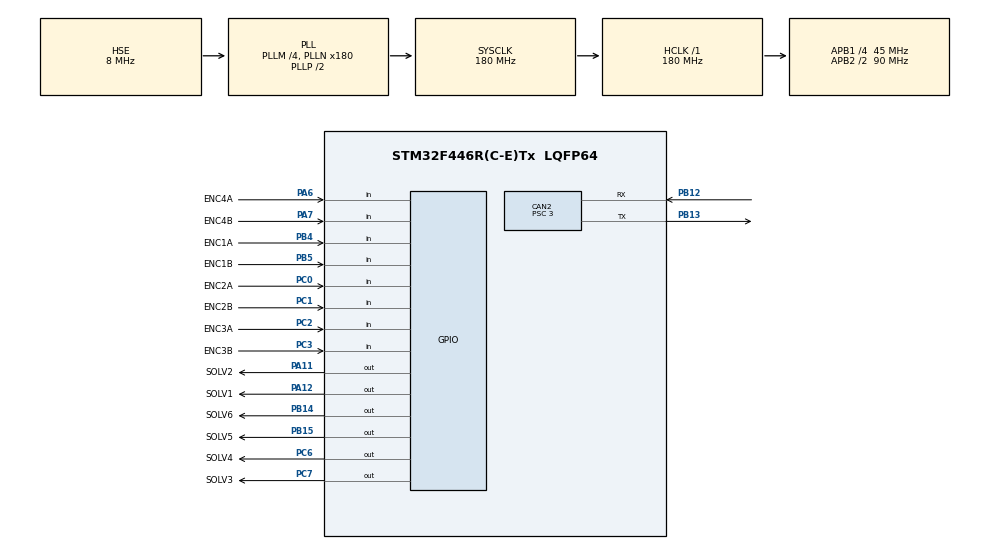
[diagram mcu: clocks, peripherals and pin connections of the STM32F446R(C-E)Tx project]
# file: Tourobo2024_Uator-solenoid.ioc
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CAN2.BS1=CAN_BS1_12TQ
CAN2.BS2=CAN_BS2_2TQ
CAN2.CalculateBaudRate=1000000
CAN2.CalculateTimeBit=1000
CAN2.CalculateTimeQuantum=66.66666666666666
CAN2.Prescaler=3
CAN2.SJW=CAN_SJW_1TQ
Mcu.Family=STM32F4
Mcu.Name=STM32F446R(C-E)Tx
Mcu.Package=LQFP64
NVIC.PriorityGroup=NVIC_PRIORITYGROUP_4
PA11.GPIO_Label=SOLV2
PA11.Signal=GPIO_Output
PA12.GPIO_Label=SOLV1
PA12.Signal=GPIO_Output
PA13.Mode=Serial_Wire
PA13.Signal=SYS_JTMS-SWDIO
PA14.Mode=Serial_Wire
PA14.Signal=SYS_JTCK-SWCLK
PA6.GPIO_Label=ENC4A
PA6.Signal=GPIO_Input
PA7.GPIO_Label=ENC4B
PA7.Signal=GPIO_Input
PB12.Mode=CAN_Activate
PB12.Signal=CAN2_RX
PB13.Mode=CAN_Activate
PB13.Signal=CAN2_TX
PB14.GPIO_Label=SOLV6
PB14.Signal=GPIO_Output
PB15.GPIO_Label=SOLV5
PB15.Signal=GPIO_Output
PB4.GPIO_Label=ENC1A
PB4.Signal=GPIO_Input
PB5.GPIO_Label=ENC1B
PB5.Signal=GPIO_Input
PC0.GPIO_Label=ENC2A
PC0.Signal=GPIO_Input
PC1.GPIO_Label=ENC2B
PC1.Signal=GPIO_Input
PC2.GPIO_Label=ENC3A
PC2.Signal=GPIO_Input
PC3.GPIO_Label=ENC3B
PC3.Signal=GPIO_Input
PC6.GPIO_Label=SOLV4
PC6.Signal=GPIO_Output
PC7.GPIO_Label=SOLV3
PC7.Signal=GPIO_Output
PH0-OSC_IN.Mode=HSE-External-Clock-Source
PH0-OSC_IN.Signal=RCC_OSC_IN
PH1-OSC_OUT.Mode=HSE-External-Clock-Source
PH1-OSC_OUT.Signal=RCC_OSC_OUT
ProjectManager.HeapSize=0x200
ProjectManager.StackSize=0x400
ProjectManager.TargetToolchain=STM32CubeIDE
RCC.AHBFreq_Value=180000000
RCC.APB1CLKDivider=RCC_HCLK_DIV4
RCC.APB1Freq_Value=45000000
RCC.APB1TimFreq_Value=90000000
RCC.APB2CLKDivider=RCC_HCLK_DIV2
RCC.APB2Freq_Value=90000000
RCC.APB2TimFreq_Value=180000000
RCC.CortexFreq_Value=180000000
RCC.HCLKFreq_Value=180000000
RCC.HSE_VALUE=8000000
RCC.PLLM=4
RCC.PLLN=180
RCC.PLLSourceVirtual=RCC_PLLSOURCE_HSE
RCC.SYSCLKFreq_VALUE=180000000
RCC.SYSCLKSource=RCC_SYSCLKSOURCE_PLLCLK
RCC.USBFreq_Value=180000000
RCC.VCOOutputFreq_Value=360000000
board=custom

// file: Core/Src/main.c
/* USER CODE BEGIN Header */
/**
  ******************************************************************************
  * @file           : main.c
  * @brief          : Main program body
  ******************************************************************************
  * @attention
  *
  * Copyright (c) 2024 STMicroelectronics.
  * All rights reserved.
  *
  * This software is licensed under terms that can be found in the LICENSE file
  * in the root directory of this software component.
  * If no LICENSE file comes with this software, it is provided AS-IS.
  *
  ******************************************************************************
  */
/* USER CODE END Header */
#include "main.h"

CAN_HandleTypeDef hcan2;

void SystemClock_Config(void);
static void MX_GPIO_Init(void);
static void MX_CAN2_Init(void);

int main(void)
{

  /* MCU Configuration--------------------------------------------------------*/

  /* Reset of all peripherals, Initializes the Flash interface and the Systick. */
  HAL_Init();

  /* Configure the system clock */
  SystemClock_Config();

  /* Initialize all configured peripherals */
  MX_GPIO_Init();
  MX_CAN2_Init();

  /* Infinite loop */
  /* USER CODE BEGIN WHILE */
  while (1)
  {
  	HAL_GPIO_TogglePin(GPIOA, GPIO_PIN_12);
  	HAL_Delay(500);
    /* USER CODE END WHILE */

  }
}

void SystemClock_Config(void)
{
  RCC_OscInitTypeDef RCC_OscInitStruct = {0};
  RCC_ClkInitTypeDef RCC_ClkInitStruct = {0};

  /** Configure the main internal regulator output voltage
  */
  __HAL_RCC_PWR_CLK_ENABLE();
  __HAL_PWR_VOLTAGESCALING_CONFIG(PWR_REGULATOR_VOLTAGE_SCALE1);

  /** Initializes the RCC Oscillators according to the specified parameters
  * in the RCC_OscInitTypeDef structure.
  */
  RCC_OscInitStruct.OscillatorType = RCC_OSCILLATORTYPE_HSE;
  RCC_OscInitStruct.HSEState = RCC_HSE_BYPASS;
  RCC_OscInitStruct.PLL.PLLState = RCC_PLL_ON;
  RCC_OscInitStruct.PLL.PLLSource = RCC_PLLSOURCE_HSE;
  RCC_OscInitStruct.PLL.PLLM = 4;
  RCC_OscInitStruct.PLL.PLLN = 180;
  RCC_OscInitStruct.PLL.PLLP = RCC_PLLP_DIV2;
  RCC_OscInitStruct.PLL.PLLQ = 2;
  RCC_OscInitStruct.PLL.PLLR = 2;
  if (HAL_RCC_OscConfig(&RCC_OscInitStruct) != HAL_OK)
  {
    Error_Handler();
  }

  /** Activate the Over-Drive mode
  */
  if (HAL_PWREx_EnableOverDrive() != HAL_OK)
  {
    Error_Handler();
  }

  /** Initializes the CPU, AHB and APB buses clocks
  */
  RCC_ClkInitStruct.ClockType = RCC_CLOCKTYPE_HCLK|RCC_CLOCKTYPE_SYSCLK
                              |RCC_CLOCKTYPE_PCLK1|RCC_CLOCKTYPE_PCLK2;
  RCC_ClkInitStruct.SYSCLKSource = RCC_SYSCLKSOURCE_PLLCLK;
  RCC_ClkInitStruct.AHBCLKDivider = RCC_SYSCLK_DIV1;
  RCC_ClkInitStruct.APB1CLKDivider = RCC_HCLK_DIV4;
  RCC_ClkInitStruct.APB2CLKDivider = RCC_HCLK_DIV2;

  if (HAL_RCC_ClockConfig(&RCC_ClkInitStruct, FLASH_LATENCY_5) != HAL_OK)
  {
    Error_Handler();
  }
}

static void MX_CAN2_Init(void)
{

  hcan2.Instance = CAN2;
  hcan2.Init.Prescaler = 3;
  hcan2.Init.Mode = CAN_MODE_NORMAL;
  hcan2.Init.SyncJumpWidth = CAN_SJW_1TQ;
  hcan2.Init.TimeSeg1 = CAN_BS1_12TQ;
  hcan2.Init.TimeSeg2 = CAN_BS2_2TQ;
  hcan2.Init.TimeTriggeredMode = DISABLE;
  hcan2.Init.AutoBusOff = DISABLE;
  hcan2.Init.AutoWakeUp = DISABLE;
  hcan2.Init.AutoRetransmission = DISABLE;
  hcan2.Init.ReceiveFifoLocked = DISABLE;
  hcan2.Init.TransmitFifoPriority = DISABLE;
  if (HAL_CAN_Init(&hcan2) != HAL_OK)
  {
    Error_Handler();
  }

}

static void MX_GPIO_Init(void)
{
  GPIO_InitTypeDef GPIO_InitStruct = {0};

  /* GPIO Ports Clock Enable */
  __HAL_RCC_GPIOH_CLK_ENABLE();
  __HAL_RCC_GPIOC_CLK_ENABLE();
  __HAL_RCC_GPIOA_CLK_ENABLE();
  __HAL_RCC_GPIOB_CLK_ENABLE();

  /*Configure GPIO pin Output Level */
  HAL_GPIO_WritePin(GPIOB, SOLV6_Pin|SOLV5_Pin, GPIO_PIN_RESET);

  /*Configure GPIO pin Output Level */
  HAL_GPIO_WritePin(GPIOC, SOLV4_Pin|SOLV3_Pin, GPIO_PIN_RESET);

  /*Configure GPIO pin Output Level */
  HAL_GPIO_WritePin(GPIOA, SOLV2_Pin|SOLV1_Pin, GPIO_PIN_RESET);

  /*Configure GPIO pins : ENC2A_Pin ENC2B_Pin ENC3A_Pin ENC3B_Pin */
  GPIO_InitStruct.Pin = ENC2A_Pin|ENC2B_Pin|ENC3A_Pin|ENC3B_Pin;
  GPIO_InitStruct.Mode = GPIO_MODE_INPUT;
  GPIO_InitStruct.Pull = GPIO_NOPULL;
  HAL_GPIO_Init(GPIOC, &GPIO_InitStruct);

  /*Configure GPIO pins : ENC4A_Pin ENC4B_Pin */
  GPIO_InitStruct.Pin = ENC4A_Pin|ENC4B_Pin;
  GPIO_InitStruct.Mode = GPIO_MODE_INPUT;
  GPIO_InitStruct.Pull = GPIO_NOPULL;
  HAL_GPIO_Init(GPIOA, &GPIO_InitStruct);

  /*Configure GPIO pins : SOLV6_Pin SOLV5_Pin */
  GPIO_InitStruct.Pin = SOLV6_Pin|SOLV5_Pin;
  GPIO_InitStruct.Mode = GPIO_MODE_OUTPUT_PP;
  GPIO_InitStruct.Pull = GPIO_NOPULL;
  GPIO_InitStruct.Speed = GPIO_SPEED_FREQ_LOW;
  HAL_GPIO_Init(GPIOB, &GPIO_InitStruct);

  /*Configure GPIO pins : SOLV4_Pin SOLV3_Pin */
  GPIO_InitStruct.Pin = SOLV4_Pin|SOLV3_Pin;
  GPIO_InitStruct.Mode = GPIO_MODE_OUTPUT_PP;
  GPIO_InitStruct.Pull = GPIO_NOPULL;
  GPIO_InitStruct.Speed = GPIO_SPEED_FREQ_LOW;
  HAL_GPIO_Init(GPIOC, &GPIO_InitStruct);

  /*Configure GPIO pins : SOLV2_Pin SOLV1_Pin */
  GPIO_InitStruct.Pin = SOLV2_Pin|SOLV1_Pin;
  GPIO_InitStruct.Mode = GPIO_MODE_OUTPUT_PP;
  GPIO_InitStruct.Pull = GPIO_NOPULL;
  GPIO_InitStruct.Speed = GPIO_SPEED_FREQ_LOW;
  HAL_GPIO_Init(GPIOA, &GPIO_InitStruct);

  /*Configure GPIO pins : ENC1A_Pin ENC1B_Pin */
  GPIO_InitStruct.Pin = ENC1A_Pin|ENC1B_Pin;
  GPIO_InitStruct.Mode = GPIO_MODE_INPUT;
  GPIO_InitStruct.Pull = GPIO_NOPULL;
  HAL_GPIO_Init(GPIOB, &GPIO_InitStruct);

}

void Error_Handler(void)
{
  __disable_irq();
  while (1)
  {
  }
}
